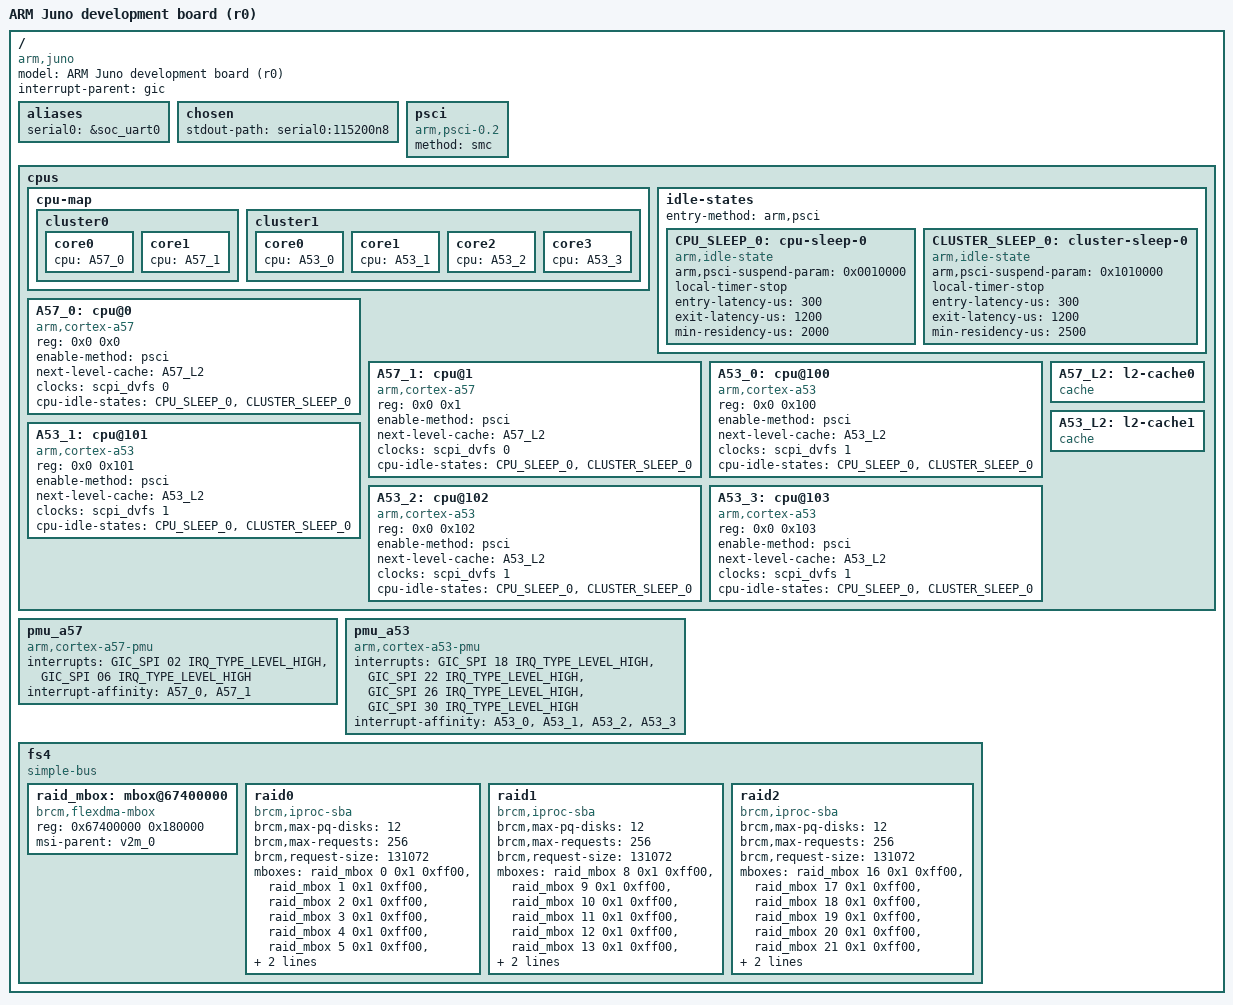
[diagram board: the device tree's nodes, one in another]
/*
 *  BSD LICENSE
 *
 *  Copyright(c) 2016 Broadcom.  All rights reserved.
 *
 *  Redistribution and use in source and binary forms, with or without
 *  modification, are permitted provided that the following conditions
 *  are met:
 *
 *    * Redistributions of source code must retain the above copyright
 *      notice, this list of conditions and the following disclaimer.
 *    * Redistributions in binary form must reproduce the above copyright
 *      notice, this list of conditions and the following disclaimer in
 *      the documentation and/or other materials provided with the
 *      distribution.
 *    * Neither the name of Broadcom Corporation nor the names of its
 *      contributors may be used to endorse or promote products derived
 *      from this software without specific prior written permission.
 *
 *  THIS SOFTWARE IS PROVIDED BY THE COPYRIGHT HOLDERS AND CONTRIBUTORS
 *  "AS IS" AND ANY EXPRESS OR IMPLIED WARRANTIES, INCLUDING, BUT NOT
 *  LIMITED TO, THE IMPLIED WARRANTIES OF MERCHANTABILITY AND FITNESS FOR
 *  A PARTICULAR PURPOSE ARE DISCLAIMED. IN NO EVENT SHALL THE COPYRIGHT
 *  OWNER OR CONTRIBUTORS BE LIABLE FOR ANY DIRECT, INDIRECT, INCIDENTAL,
 *  SPECIAL, EXEMPLARY, OR CONSEQUENTIAL DAMAGES (INCLUDING, BUT NOT
 *  LIMITED TO, PROCUREMENT OF SUBSTITUTE GOODS OR SERVICES; LOSS OF USE,
 *  DATA, OR PROFITS; OR BUSINESS INTERRUPTION) HOWEVER CAUSED AND ON ANY
 *  THEORY OF LIABILITY, WHETHER IN CONTRACT, STRICT LIABILITY, OR TORT
 *  (INCLUDING NEGLIGENCE OR OTHERWISE) ARISING IN ANY WAY OUT OF THE USE
 * OF THIS SOFTWARE, EVEN IF ADVISED OF THE POSSIBILITY OF SUCH DAMAGE.
 */

/dts-v1/;

#include <dt-bindings/interrupt-controller/arm-gic.h>

/ {
	model = "ARM Juno development board (r0)";
	compatible = "arm,juno", "arm,vexpress";
	interrupt-parent = <&gic>;
	#address-cells = <2>;
	#size-cells = <2>;

	aliases {
		serial0 = &soc_uart0;
	};

	chosen {
		stdout-path = "serial0:115200n8";
	};

	psci {
		compatible = "arm,psci-0.2";
		method = "smc";
	};

	cpus {
		#address-cells = <2>;
		#size-cells = <0>;

		cpu-map {
			cluster0 {
				core0 {
					cpu = <&A57_0>;
				};
				core1 {
					cpu = <&A57_1>;
				};
			};

			cluster1 {
				core0 {
					cpu = <&A53_0>;
				};
				core1 {
					cpu = <&A53_1>;
				};
				core2 {
					cpu = <&A53_2>;
				};
				core3 {
					cpu = <&A53_3>;
				};
			};
		};

		idle-states {
			entry-method = "arm,psci";

			CPU_SLEEP_0: cpu-sleep-0 {
				compatible = "arm,idle-state";
				arm,psci-suspend-param = <0x0010000>;
				local-timer-stop;
				entry-latency-us = <300>;
				exit-latency-us = <1200>;
				min-residency-us = <2000>;
			};

			CLUSTER_SLEEP_0: cluster-sleep-0 {
				compatible = "arm,idle-state";
				arm,psci-suspend-param = <0x1010000>;
				local-timer-stop;
				entry-latency-us = <300>;
				exit-latency-us = <1200>;
				min-residency-us = <2500>;
			};
		};

		A57_0: cpu@0 {
			compatible = "arm,cortex-a57","arm,armv8";
			reg = <0x0 0x0>;
			device_type = "cpu";
			enable-method = "psci";
			next-level-cache = <&A57_L2>;
			clocks = <&scpi_dvfs 0>;
			cpu-idle-states = <&CPU_SLEEP_0 &CLUSTER_SLEEP_0>;
		};

		A57_1: cpu@1 {
			compatible = "arm,cortex-a57","arm,armv8";
			reg = <0x0 0x1>;
			device_type = "cpu";
			enable-method = "psci";
			next-level-cache = <&A57_L2>;
			clocks = <&scpi_dvfs 0>;
			cpu-idle-states = <&CPU_SLEEP_0 &CLUSTER_SLEEP_0>;
		};

		A53_0: cpu@100 {
			compatible = "arm,cortex-a53","arm,armv8";
			reg = <0x0 0x100>;
			device_type = "cpu";
			enable-method = "psci";
			next-level-cache = <&A53_L2>;
			clocks = <&scpi_dvfs 1>;
			cpu-idle-states = <&CPU_SLEEP_0 &CLUSTER_SLEEP_0>;
		};

		A53_1: cpu@101 {
			compatible = "arm,cortex-a53","arm,armv8";
			reg = <0x0 0x101>;
			device_type = "cpu";
			enable-method = "psci";
			next-level-cache = <&A53_L2>;
			clocks = <&scpi_dvfs 1>;
			cpu-idle-states = <&CPU_SLEEP_0 &CLUSTER_SLEEP_0>;
		};

		A53_2: cpu@102 {
			compatible = "arm,cortex-a53","arm,armv8";
			reg = <0x0 0x102>;
			device_type = "cpu";
			enable-method = "psci";
			next-level-cache = <&A53_L2>;
			clocks = <&scpi_dvfs 1>;
			cpu-idle-states = <&CPU_SLEEP_0 &CLUSTER_SLEEP_0>;
		};

		A53_3: cpu@103 {
			compatible = "arm,cortex-a53","arm,armv8";
			reg = <0x0 0x103>;
			device_type = "cpu";
			enable-method = "psci";
			next-level-cache = <&A53_L2>;
			clocks = <&scpi_dvfs 1>;
			cpu-idle-states = <&CPU_SLEEP_0 &CLUSTER_SLEEP_0>;
		};

		A57_L2: l2-cache0 {
			compatible = "cache";
		};

		A53_L2: l2-cache1 {
			compatible = "cache";
		};
	};

	pmu_a57 {
		compatible = "arm,cortex-a57-pmu";
		interrupts = <GIC_SPI 02 IRQ_TYPE_LEVEL_HIGH>,
			     <GIC_SPI 06 IRQ_TYPE_LEVEL_HIGH>;
		interrupt-affinity = <&A57_0>,
				     <&A57_1>;
	};

	pmu_a53 {
		compatible = "arm,cortex-a53-pmu";
		interrupts = <GIC_SPI 18 IRQ_TYPE_LEVEL_HIGH>,
			     <GIC_SPI 22 IRQ_TYPE_LEVEL_HIGH>,
			     <GIC_SPI 26 IRQ_TYPE_LEVEL_HIGH>,
			     <GIC_SPI 30 IRQ_TYPE_LEVEL_HIGH>;
		interrupt-affinity = <&A53_0>,
				     <&A53_1>,
				     <&A53_2>,
				     <&A53_3>;
	};

	#include "juno-base.dtsi"

	fs4: fs4 {
		compatible = "simple-bus";
		#address-cells = <1>;
		#size-cells = <1>;
		ranges = <0 0 0 0xffffffff>;

		raid_mbox: mbox@67400000 {
			compatible = "brcm,flexdma-mbox";
			/*
			 * Note: We only have 32 SPIs in Juno GICv2m
			 * and we save 8 SPIs for Juno PCIe. This gives
			 * us only 24 SPIs of Juno GICv2m for FS4 RAID
			 * hence we only use first 24 rings of FS4 RAID.
			 */
			reg = <0x67400000 0x180000>;
			msi-parent = <&v2m_0>;
			#mbox-cells = <3>;
		};

		raid0 {
			compatible = "brcm,iproc-sba";
			brcm,max-pq-disks = <12>;
			brcm,max-requests = <256>;
			brcm,request-size = <131072>;
			mboxes = <&raid_mbox 0 0x1 0xff00>,
				 <&raid_mbox 1 0x1 0xff00>,
				 <&raid_mbox 2 0x1 0xff00>,
				 <&raid_mbox 3 0x1 0xff00>,
				 <&raid_mbox 4 0x1 0xff00>,
				 <&raid_mbox 5 0x1 0xff00>,
				 <&raid_mbox 6 0x1 0xff00>,
				 <&raid_mbox 7 0x1 0xff00>;
		};

		raid1 {
			compatible = "brcm,iproc-sba";
			brcm,max-pq-disks = <12>;
			brcm,max-requests = <256>;
			brcm,request-size = <131072>;
			mboxes = <&raid_mbox 8 0x1 0xff00>,
				 <&raid_mbox 9 0x1 0xff00>,
				 <&raid_mbox 10 0x1 0xff00>,
				 <&raid_mbox 11 0x1 0xff00>,
				 <&raid_mbox 12 0x1 0xff00>,
				 <&raid_mbox 13 0x1 0xff00>,
				 <&raid_mbox 14 0x1 0xff00>,
				 <&raid_mbox 15 0x1 0xff00>;
		};

		raid2 {
			compatible = "brcm,iproc-sba";
			brcm,max-pq-disks = <12>;
			brcm,max-requests = <256>;
			brcm,request-size = <131072>;
			mboxes = <&raid_mbox 16 0x1 0xff00>,
				 <&raid_mbox 17 0x1 0xff00>,
				 <&raid_mbox 18 0x1 0xff00>,
				 <&raid_mbox 19 0x1 0xff00>,
				 <&raid_mbox 20 0x1 0xff00>,
				 <&raid_mbox 21 0x1 0xff00>,
				 <&raid_mbox 22 0x1 0xff00>,
				 <&raid_mbox 23 0x1 0xff00>;
		};
	};
};
